# CMS32L051 register map
Vendor: CMS; Series: CMS32L051; File version: 1.2
CPU: CM0+ r0p1, little endian, no MPU, no FPU, VTOR, 2 interrupt priority bits
Registers are 8-bit, read-write, reset 0x0 unless marked. A register's access mark holds for its fields unless they carry their own. Offsets are from the block's base; [hi:lo] are bit positions; {n}, {i} and the like mark numbered series; 'fields as' and 'values as' point back to an identical list.

## PCBZ — Clock/Buzzer output controller
Base 0x40040FA0
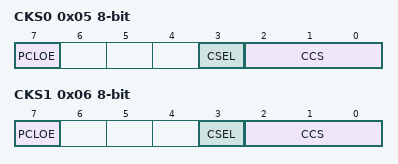
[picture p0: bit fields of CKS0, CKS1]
0x05 CKS0 — Clock output select registers 0
  [7] PCLOE — PCLBUZn pin output enable
  [3] CSEL — PCLBUZn output clock select
  [2:0] CCS — PCLBUZn output clock select
0x06 CKS1 — Clock output select registers 1
  fields as CKS0

## WDT — Watchdog Timer with window
Base 0x40020404
0x01 LOCKCTL (reset mask 0x1) — Lockup Watchdog timer enable register
0x02 PRCR — Lockup Watchdog timer enable protect register
0xBFD WDTE (reset mask 0xAC) — Watchdog timer enable register

## ADC — A/D Converter
Base 0x40045000
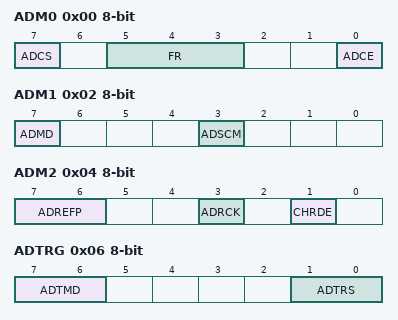
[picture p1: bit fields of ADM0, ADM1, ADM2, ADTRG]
0x00 ADM0 — A/D mode register 0
  [7] ADCS — A/D conversion operation control
  [5:3] FR — A/D conversion clock (fAD) select
  [0] ADCE — A/D enable
0x02 ADM1 — A/D mode register 1
  [7] ADMD — A/D conversion channel select mode
    0=Select mode; 1=Scan mode
  [3] ADSCM — A/D conversion mode
    0=Sequential conversion mode; 1=One-shot conversion mode
0x04 ADM2 — A/D mode register 2
  [7:6] ADREFP — Selection of the + side reference voltage of A/D converter
    0=VDD (Supplied from VDD); 1=AVREFP0 (Supplied from AVREFP); 2=AVREFP1 (Supplied from inside AVREF of A/D)
  [3] ADRCK — the upper limit and lower limit conversion result values
  [1] CHRDE — output CH number in A/D conversion result in Scan mode
0x06 ADTRG (reset mask 0x33) — A/D mode register 2
  [7:6] ADTMD — A/D conversion trigger mode
  [1:0] ADTRS — A/D hard trigger select
0x08 ADS (reset mask 0xBF) — Analog input channel specification register
0x0A ADLL — Conversion result comparison lower limit setting register
0x0B ADUL reset 0xFF — Conversion result comparison upper limit setting register
0x0E ADCR 16-bit (reset mask 0xFFF) — 12-bit A/D conversion result register
0x0F ADCRH (alternate view of ADCR) — Higher 8-bit A/D conversion result register
0x15 ADSMPWAIT — A/D sampling wait control register

## SCI0 — Serial Communication Interface 0 with UART, SPI and simplified I2C supported
Base 0x40041100
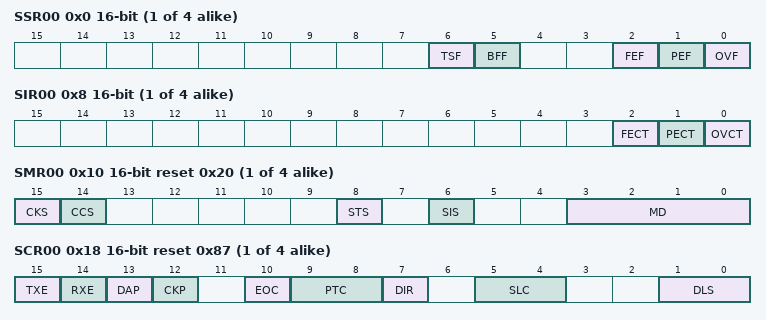
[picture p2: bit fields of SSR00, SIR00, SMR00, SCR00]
{0x0+2i} SSR{i:02} 16-bit ro (i=0..3) — Serial status register mn
  [6] TSF — Communication status indication flag of channel n
  [5] BFF — Buffer register status indication flag of channel n
  [2] FEF — Framing error detection flag of channel n
  [1] PEF — Parity error detection flag of channel n
  [0] OVF — Overrun error detection flag of channel n
{0x8+2i} SIR{i:02} 16-bit (i=0..3) — Serial flag clear trigger register mn
  [2] FECT — Clear trigger of framing error flag of channel n
  [1] PECT — Clear trigger of parity error flag of channel n
  [0] OVCT — Clear trigger of overrun error flag of channel n
{0x10+2i} SMR{i:02} 16-bit reset 0x20 (reset mask 0xC147) (i=0..3) — Serial mode register mn
  [15] CKS — Selection of operation clock (fMCK) of channel n
  [14] CCS — Selection of transfer clock (fTCLK) of channel n
  [8] STS — Selection of start trigger source
  [6] SIS — Controls inversion of level of receive data of channel n in UART mode
  [3:0] MD — Setting of operation mode of channel n
{0x18+2i} SCR{i:02} 16-bit reset 0x87 (i=0..3) — Serial communication operation setting register mn
  [15] TXE — Transmission enable
  [14] RXE — Reception enable
  [13] DAP — Selection of data phase in SPI mode
  [12] CKP — Selection of clock phase in SPI mode
  [10] EOC — Mask control of error interrupt signal (INTSREx (x = 0 to 2))
  [9:8] PTC — Setting of parity bit in UART mode
  [7] DIR — Selection of data transfer sequence in SPI and UART modes
  [5:4] SLC — Setting of stop bit in UART mode
  [1:0] DLS — Setting of data length in SPI and UART modes
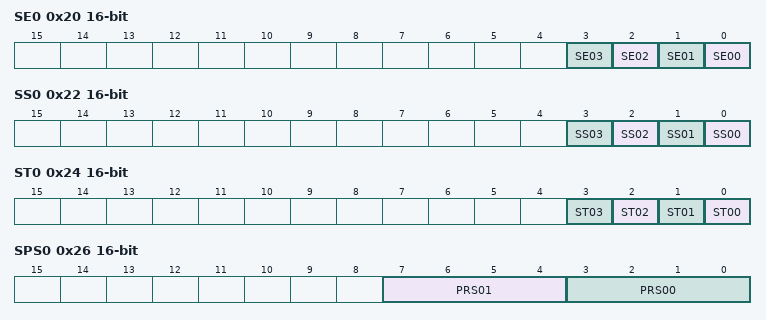
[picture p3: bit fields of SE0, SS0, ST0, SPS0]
0x20 SE0 16-bit ro — Serial channel enable status register m
  [n] SE{n:02} (n=0..3) — Indication of operation enable/stop status of channel {n}
0x22 SS0 16-bit — Serial channel start register 0
  [n] SS{n:02} (n=0..3) — Operation start trigger of channel {n}
0x24 ST0 16-bit — Serial channel stop register 0
  [n] ST{n:02} (n=0..3) — Operation stop trigger of channel {n}
0x26 SPS0 16-bit — Serial clock select register 0
  [7:4] PRS01 — Prescaler 1
  [3:0] PRS00 — Prescaler 0
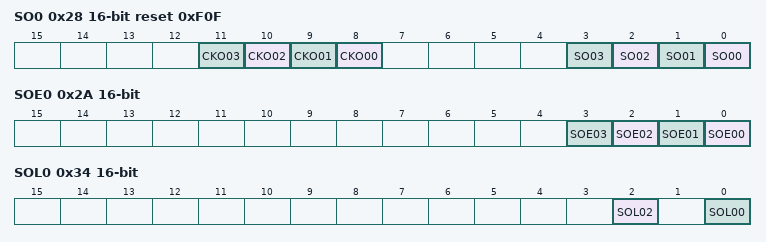
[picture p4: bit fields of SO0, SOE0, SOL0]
0x28 SO0 16-bit reset 0xF0F — Serial output register 0
  [n+8] CKO{n:02} (n=0..3) — Serial clock output of channel {n}
  [n] SO{n:02} (n=0..3) — Serial data output of channel {n}
0x2A SOE0 16-bit — Serial output enable register 0
  [n] SOE{n:02} (n=0..3) — Serial output enable of channel {n}
0x34 SOL0 16-bit — Serial output level register 0
  [2] SOL02 — Selects inversion of the level of the transmit data of channel n in UART mode
  [0] SOL00 — Selects inversion of the level of the transmit data of channel n in UART mode
{0x210+2i} SDR0{i} (i=0..1) 16-bit — Serial data register 0{i}
0x210 SIO00 (alternate view of SDR00) — SPI data register
0x210 TXD0 (alternate view of SDR00) — UART transmit data register
0x212 SIO01 (alternate view of SDR01) — SPI data register
0x212 RXD0 (alternate view of SDR01) — UART receive data register
{0x240+2i} SDR0{i} (i=2..3) 16-bit — Serial data register 0{i}
0x244 SIO10 (alternate view of SDR02) — SPI data register
0x244 TXD1 (alternate view of SDR02) — UART transmit data register
0x246 SIO11 (alternate view of SDR03) — SPI data register
0x246 RXD1 (alternate view of SDR03) — UART receive data register
